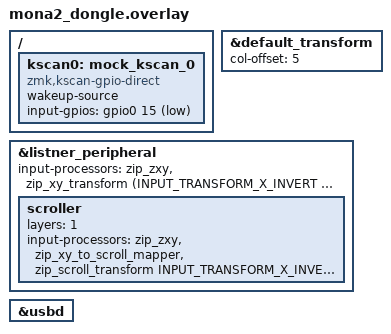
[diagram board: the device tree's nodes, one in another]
#include "mona2_kb.dtsi"
#include "mona2_pointer.dtsi"
#include <input/processors/xyz.dtsi>

/ {
 
    kscan0: mock_kscan_0 {
        // compatible = "zmk,kscan-mock";
        // columns = <1>;
        // rows = <1>;
        // events = <0>;

        compatible = "zmk,kscan-gpio-direct";
        wakeup-source;
        input-gpios
            = <&gpio0 15 (GPIO_ACTIVE_LOW | GPIO_PULL_UP)>;
    };  
};

&default_transform {
    col-offset = <5>;
};

&listner_peripheral {
    status = "okay";
    input-processors =  <&zip_zxy>,<&zip_xy_transform (INPUT_TRANSFORM_X_INVERT | INPUT_TRANSFORM_Y_INVERT)>;
    scroller {
        layers = <1>;
        input-processors = <&zip_zxy>,<&zip_xy_to_scroll_mapper>, <&zip_scroll_transform INPUT_TRANSFORM_X_INVERT>;
    };
};

zephyr_udc0: &usbd {
    status = "okay";
};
